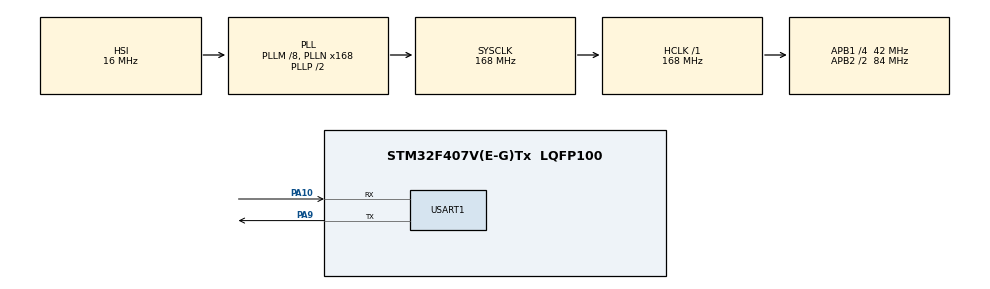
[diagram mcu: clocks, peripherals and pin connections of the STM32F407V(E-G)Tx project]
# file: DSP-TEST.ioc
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Mcu.Family=STM32F4
Mcu.Name=STM32F407V(E-G)Tx
Mcu.Package=LQFP100
NVIC.PriorityGroup=NVIC_PRIORITYGROUP_4
NVIC.TIM1_UP_TIM10_IRQn=true\:15\:0\:false\:false\:true\:false\:true\:true
NVIC.TimeBase=TIM1_UP_TIM10_IRQn
NVIC.TimeBaseIP=TIM1
PA10.Mode=Asynchronous
PA10.Signal=USART1_RX
PA13.Mode=Serial_Wire
PA13.Signal=SYS_JTMS-SWDIO
PA14.Mode=Serial_Wire
PA14.Signal=SYS_JTCK-SWCLK
PA9.Mode=Asynchronous
PA9.Signal=USART1_TX
PH0-OSC_IN.Mode=HSE-External-Oscillator
PH0-OSC_IN.Signal=RCC_OSC_IN
PH1-OSC_OUT.Mode=HSE-External-Oscillator
PH1-OSC_OUT.Signal=RCC_OSC_OUT
ProjectManager.HeapSize=0x200
ProjectManager.StackSize=0x400
ProjectManager.TargetToolchain=CMake
RCC.48MHZClocksFreq_Value=84000000
RCC.AHBFreq_Value=168000000
RCC.APB1CLKDivider=RCC_HCLK_DIV4
RCC.APB1Freq_Value=42000000
RCC.APB1TimFreq_Value=84000000
RCC.APB2CLKDivider=RCC_HCLK_DIV2
RCC.APB2Freq_Value=84000000
RCC.APB2TimFreq_Value=168000000
RCC.CortexFreq_Value=168000000
RCC.HCLKFreq_Value=168000000
RCC.HSE_VALUE=25000000
RCC.HSI_VALUE=16000000
RCC.LSE_VALUE=32768
RCC.PLLM=8
RCC.PLLN=168
RCC.SYSCLKFreq_VALUE=168000000
RCC.SYSCLKSource=RCC_SYSCLKSOURCE_PLLCLK
RCC.VCOOutputFreq_Value=336000000
STMicroelectronics.X-CUBE-ALGOBUILD.1.4.0.LibraryCcDSPOoLibraryJjDSPOoLibrary=true
USART1.VirtualMode=VM_ASYNC
VP_STMicroelectronics.X-CUBE-ALGOBUILD_VS_DSPOoLibraryJjLibrary_1.4.0_1.4.0.Mode=DSPOoLibraryJjLibrary
VP_SYS_VS_tim1.Mode=TIM1
board=custom

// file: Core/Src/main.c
/* USER CODE BEGIN Header */
/**
 ******************************************************************************
 * @file           : main.c
 * @brief          : Main program body
 ******************************************************************************
 * @attention
 *
 * Copyright (c) 2025 STMicroelectronics.
 * All rights reserved.
 *
 * This software is licensed under terms that can be found in the LICENSE file
 * in the root directory of this software component.
 * If no LICENSE file comes with this software, it is provided AS-IS.
 *
 ******************************************************************************
 */
/* USER CODE END Header */
#include "main.h"
#include "usart.h"
#include "gpio.h"

/* USER CODE BEGIN Includes */
#include "arm_math.h"
#include <stdio.h>
/* USER CODE END Includes */

/* USER CODE BEGIN PTD */
__weak int _write(int file, char *ptr, int len)
{
  // 实现输出逻辑（例如通过串口发送数据）
  HAL_UART_Transmit(&huart1, (uint8_t *)ptr, len, 100);
  return len;
}
/* USER CODE END PTD */

/* USER CODE BEGIN PD */
#define FFT_POINTS 256  // 采样点总数
#define SAMPLE_FREQ 256 // 采样频率
#define SINE_FREQ 10     //
/* USER CODE END PD */

/* USER CODE BEGIN PV */

float32_t inputSignal[FFT_POINTS] = {0};
float32_t outputSignal[FFT_POINTS] = {0};
float32_t magSignal[FFT_POINTS / 2] = {0};
/* USER CODE END PV */

void SystemClock_Config(void);

int main(void)
{

  /* USER CODE BEGIN 1 */
  arm_rfft_fast_instance_f32 S;
  arm_rfft_fast_init_f32(&S, FFT_POINTS);
  /* USER CODE END 1 */

  /* MCU Configuration--------------------------------------------------------*/

  /* Reset of all peripherals, Initializes the Flash interface and the Systick. */
  HAL_Init();

  /* Configure the system clock */
  SystemClock_Config();

  /* Initialize all configured peripherals */
  MX_GPIO_Init();
  MX_USART1_UART_Init();
  /* USER CODE BEGIN 2 */
  for (int x = 0; x < FFT_POINTS; x++)
  {
    // y(t)=sin(2πft)
    inputSignal[x] = arm_sin_f32(2 * PI * SINE_FREQ * x / SAMPLE_FREQ);
    // printf("%.3f\n", inputSignal[x]);
    // HAL_Delay(1); // 避免数据拥堵
  }
  printf("开始啦1\n");
  arm_rfft_fast_f32(&S, inputSignal, outputSignal, 0);
  printf("开始啦\n");
  arm_cmplx_mag_f32(outputSignal, magSignal, FFT_POINTS / 2);
  printf("准备进入循环\n");
  for (int i = 0; i < FFT_POINTS / 2; i++)
  {
    printf("i = %d %.3f\n",i*SAMPLE_FREQ/FFT_POINTS, magSignal[i]);
    HAL_Delay(1);
  }
  /* USER CODE END 2 */

  /* Infinite loop */
  while (1)
  {

  }
}

void SystemClock_Config(void)
{
  RCC_OscInitTypeDef RCC_OscInitStruct = {0};
  RCC_ClkInitTypeDef RCC_ClkInitStruct = {0};

  /** Configure the main internal regulator output voltage
   */
  __HAL_RCC_PWR_CLK_ENABLE();
  __HAL_PWR_VOLTAGESCALING_CONFIG(PWR_REGULATOR_VOLTAGE_SCALE1);

  /** Initializes the RCC Oscillators according to the specified parameters
   * in the RCC_OscInitTypeDef structure.
   */
  RCC_OscInitStruct.OscillatorType = RCC_OSCILLATORTYPE_HSI;
  RCC_OscInitStruct.HSIState = RCC_HSI_ON;
  RCC_OscInitStruct.HSICalibrationValue = RCC_HSICALIBRATION_DEFAULT;
  RCC_OscInitStruct.PLL.PLLState = RCC_PLL_ON;
  RCC_OscInitStruct.PLL.PLLSource = RCC_PLLSOURCE_HSI;
  RCC_OscInitStruct.PLL.PLLM = 8;
  RCC_OscInitStruct.PLL.PLLN = 168;
  RCC_OscInitStruct.PLL.PLLP = RCC_PLLP_DIV2;
  RCC_OscInitStruct.PLL.PLLQ = 4;
  if (HAL_RCC_OscConfig(&RCC_OscInitStruct) != HAL_OK)
  {
    Error_Handler();
  }

  /** Initializes the CPU, AHB and APB buses clocks
   */
  RCC_ClkInitStruct.ClockType = RCC_CLOCKTYPE_HCLK | RCC_CLOCKTYPE_SYSCLK | RCC_CLOCKTYPE_PCLK1 | RCC_CLOCKTYPE_PCLK2;
  RCC_ClkInitStruct.SYSCLKSource = RCC_SYSCLKSOURCE_PLLCLK;
  RCC_ClkInitStruct.AHBCLKDivider = RCC_SYSCLK_DIV1;
  RCC_ClkInitStruct.APB1CLKDivider = RCC_HCLK_DIV4;
  RCC_ClkInitStruct.APB2CLKDivider = RCC_HCLK_DIV2;

  if (HAL_RCC_ClockConfig(&RCC_ClkInitStruct, FLASH_LATENCY_5) != HAL_OK)
  {
    Error_Handler();
  }
}

void HAL_TIM_PeriodElapsedCallback(TIM_HandleTypeDef *htim)
{
  if (htim->Instance == TIM1)
  {
    HAL_IncTick();
  }
}

void Error_Handler(void)
{
  __disable_irq();
  while (1)
  {
  }
}
